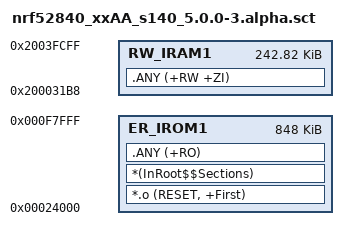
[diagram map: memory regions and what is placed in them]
; nRF5 SDK for Mesh Application scatter file -- Generated 2017-12-08 13:44:31 by tools/linker/linker_file_generator.py.
; 24 kB FLASH and 768 B RAM reserved for bootloader.
;
; This file is intended for nrf52840_xxAA with the s140_5.0.0-3.alpha SoftDevice.

LR_IROM1 0x24000 0xd4000 {
  ER_IROM1 0x24000 0xd4000 {
   *.o (RESET, +First)
   *(InRoot$$Sections)
   .ANY (+RO)
  }

  RW_IRAM1 0x200031b8 0x3cb48 {
   .ANY (+RW +ZI)
  }
}
